# M481_v1 register map
File version: 1.0
Registers are 32-bit, read-write, reset 0x0 unless marked. A register's access mark holds for its fields unless they carry their own. Offsets are from the block's base; [hi:lo] are bit positions.

## OPA — OPA Register Map
Base 0x40046000
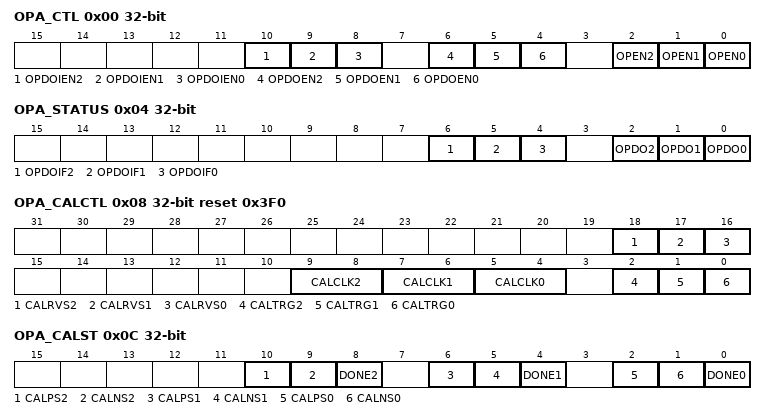
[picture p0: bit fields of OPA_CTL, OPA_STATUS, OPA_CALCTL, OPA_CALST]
0x00 OPA_CTL — OP Amplifier Control Register
  [10] OPDOIEN2 — OP Amplifier 2 Schmitt Trigger Digital Output Interrupt Enable Bit. Note: The OPDOIF2 interrupt flag is set by hardware whenever the OP amplifier 2 Schmitt trigger non-inverting buffer digital output changes state, in the meanwhile, if OPDOIEN2 is set to 1, a comparator interrupt request is generated.
    0=OP Amplifier 2 digital output interrupt function Disabled; 1=OP Amplifier 2 digital output interrupt function Enabled
  [9] OPDOIEN1 — OP Amplifier 1 Schmitt Trigger Digital Output Interrupt Enable Bit. Note: The OPDOIF1 interrupt flag is set by hardware whenever the OP amplifier 1 Schmitt trigger non-inverting buffer digital output changes state, in the meanwhile, if OPDOIEN1 is set to 1, a comparator interrupt request is generated.
    0=OP Amplifier 1 digital output interrupt function Disabled; 1=OP Amplifier 1 digital output interrupt function Enabled
  [8] OPDOIEN0 — OP Amplifier 0 Schmitt Trigger Digital Output Interrupt Enable Bit. Note: The OPDOIF0 interrupt flag is set by hardware whenever the OP amplifier 0 Schmitt trigger non-inverting buffer digital output changes state, in the meanwhile, if OPDOIEN0 is set to 1, a comparator interrupt request is generated.
    0=OP Amplifier 0 digital output interrupt function Disabled; 1=OP Amplifier 0 digital output interrupt function Enabled
  [6] OPDOEN2 — OP Amplifier 2 Schmitt Trigger Non-inverting Buffer Enable Bit
    0=OP amplifier2 schmitt trigger non-invert buffer Disabled; 1=OP amplifier2 schmitt trigger non-invert buffer Enabled
  [5] OPDOEN1 — OP Amplifier 1 Schmitt Trigger Non-inverting Buffer Enable Bit
    0=OP amplifier1 schmitt trigger non-invert buffer Disabled; 1=OP amplifier1 schmitt trigger non-invert buffer Enabled
  [4] OPDOEN0 — OP Amplifier 0 Schmitt Trigger Non-inverting Buffer Enable Bit
    0=OP amplifier0 schmitt trigger non-invert buffer Disabled; 1=OP amplifier0 schmitt trigger non-invert buffer Enabled
  [2] OPEN2 — OP Amplifier 2 Enable Bit. Note: OP Amplifier 2 output needs wait stable 20s after OPEN2 is set.
    0=OP amplifier2 Disabled; 1=OP amplifier2 Enabled
  [1] OPEN1 — OP Amplifier 1 Enable Bit. Note: OP Amplifier 1 output needs wait stable 20s after OPEN1 is set.
    0=OP amplifier1 Disabled; 1=OP amplifier1 Enabled
  [0] OPEN0 — OP Amplifier 0 Enable Bit. Note: OP Amplifier 0 output needs wait stable 20s after OPEN0 is set.
    0=OP amplifier0 Disabled; 1=OP amplifier0 Enabled
0x04 OPA_STATUS — OP Amplifier Status Register
  [6] OPDOIF2 — OP Amplifier 2 Schmitt Trigger Digital Output Interrupt Flag. OPDOIF2 interrupt flag is set by hardware whenever the OP amplifier 2 Schmitt trigger non-inverting buffer digital output changes state. This bit is cleared by writing 1 to it.
  [5] OPDOIF1 — OP Amplifier 1 Schmitt Trigger Digital Output Interrupt Flag. OPDOIF1 interrupt flag is set by hardware whenever the OP amplifier 1 Schmitt trigger non-inverting buffer digital output changes state. This bit is cleared by writing 1 to it.
  [4] OPDOIF0 — OP Amplifier 0 Schmitt Trigger Digital Output Interrupt Flag. OPDOIF0 interrupt flag is set by hardware whenever the OP amplifier 0 Schmitt trigger non-inverting buffer digital output changes state. This bit is cleared by writing 1 to it.
  [2] OPDO2 — OP Amplifier 2 Digital Output
  [1] OPDO1 — OP Amplifier 1 Digital Output
  [0] OPDO0 — OP Amplifier 0 Digital Output
0x08 OPA_CALCTL reset 0x3F0 — OP Amplifier Calibration Control Register
  [18] CALRVS2 — OPA2 Calibration Reference Voltage Selection
    0=VREF is; 1=VREF from high vcm to low vcm
  [17] CALRVS1 — OPA1 Calibration Reference Voltage Selection
    0=VREF is; 1=VREF from high vcm to low vcm
  [16] CALRVS0 — OPA0 Calibration Reference Voltage Selection
    0=VREF is; 1=VREF from high vcm to low vcm
  [9:8] CALCLK2 — OP Amplifier 2 Calibration Clock Rate Selection
    0=1 kHz
  [7:6] CALCLK1 — OP Amplifier 1 Calibration Clock Rate Selection
    0=1 kHz
  [5:4] CALCLK0 — OP Amplifier 0 Calibration Clock Rate Selection
    0=1 kHz
  [2] CALTRG2 — OP Amplifier 2 Calibration Trigger Bit. Note 1: Before this bit is enabled, OPEN2 should be set and the internal high speed RC oscillator (HIRC) should be enabled in advance. Note 2: Hardware will auto clear this bit when calibration is finished.
    0=Calibration is stopped,; 1=Calibration is triggered
  [1] CALTRG1 — OP Amplifier 1 Calibration Trigger Bit. Note 1: Before this bit is enabled, OPEN1 should be set and the internal high speed RC oscillator (HIRC) should be enabled in advance. Note 2: Hardware will auto clear this bit when calibration is finished.
    0=Calibration is stopped; 1=Calibration is triggered
  [0] CALTRG0 — OP Amplifier 0 Calibration Trigger Bit. Note 1: Before this bit is enabled, OPEN0 should be set and the internal high speed RC oscillator (HIRC) should be enabled in advance. Note 2: Hardware will auto clear this bit when calibration is finished.
    0=Calibration is stopped; 1=Calibration is triggered
0x0C OPA_CALST ro — OP Amplifier Calibration Status Register
  [10] CALPS2 — OP Amplifier 2 Calibration Result Status for PMOS
    0=Pass; 1=Fail
  [9] CALNS2 — OP Amplifier 2 Calibration Result Status for NMOS
    0=Pass; 1=Fail
  [8] DONE2 — OP Amplifier 2 Calibration Done Status
    0=Calibrating; 1=Calibration Done
  [6] CALPS1 — OP Amplifier 1 Calibration Result Status for PMOS
    0=Pass; 1=Fail
  [5] CALNS1 — OP Amplifier 1 Calibration Result Status for NMOS
    0=Pass; 1=Fail
  [4] DONE1 — OP Amplifier 1 Calibration Done Status
    0=Calibrating; 1=Calibration Done
  [2] CALPS0 — OP Amplifier 0 Calibration Result Status for PMOS
    0=Pass; 1=Fail
  [1] CALNS0 — OP Amplifier 0 Calibration Result Status for NMOS
    0=Pass; 1=Fail
  [0] DONE0 — OP Amplifier 0 Calibration Done Status
    0=Calibrating; 1=Calibration Done
